# SERDES_16G0 register map
Vendor: Texas Instruments
Registers are 32-bit, read-write, reset 0x0 unless marked. A register's access mark holds for its fields unless they carry their own. Offsets are as the file gives them; [hi:lo] are bit positions; {n}, {i} and the like mark numbered series; 'fields as' and 'values as' point back to an identical list.

## SERDES_16G0 (part 4 of 5)
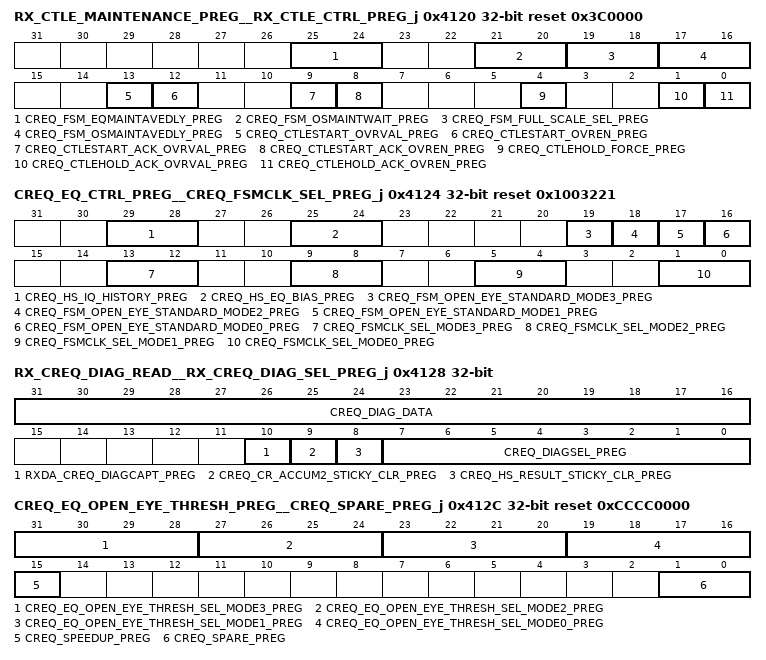
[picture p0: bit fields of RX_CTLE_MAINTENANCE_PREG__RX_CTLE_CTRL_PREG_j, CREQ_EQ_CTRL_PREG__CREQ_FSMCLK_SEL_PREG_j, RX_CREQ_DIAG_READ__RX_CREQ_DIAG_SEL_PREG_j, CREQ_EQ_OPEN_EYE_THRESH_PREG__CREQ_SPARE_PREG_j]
0x4120 RX_CTLE_MAINTENANCE_PREG__RX_CTLE_CTRL_PREG_j reset 0x3C0000 — Receive clock path CTLE Control register. Offset = 4120h + (j * 400h); where j = 0h to 1h
  [25:24] CREQ_FSM_EQMAINTAVEDLY_PREG — Receive clock path CTLE equalization maintenance averaging timer:
  [21:20] CREQ_FSM_OSMAINTWAIT_PREG — Receive clock path CTLE offset calibration maintenance hold off timer:
  [19:18] CREQ_FSM_FULL_SCALE_SEL_PREG — Offset maintenance filter threshold.
  [17:16] CREQ_FSM_OSMAINTAVEDLY_PREG — Receive clock path CTLE offset calibration maintenance =averaging timer:
  [13] CREQ_CTLESTART_OVRVAL_PREG — When creq_ctlestart_ovren_preg is asserted this value overrides the receive clock path CTLE FSM start signal from the clock path controller.
  [12] CREQ_CTLESTART_OVREN_PREG — Receive clock path CTLE start active high override enable.
  [9] CREQ_CTLESTART_ACK_OVRVAL_PREG — When creq_ctlestart_ack_ovren_preg is asserted this value overrides the receive clock path CTLE FSM start signal acknowledge to the clock path controller.
  [8] CREQ_CTLESTART_ACK_OVREN_PREG — Receive clock path CTLE start acknowledge active high override enable.
  [4] CREQ_CTLEHOLD_FORCE_PREG — Receive clock path CTLE FSM hold active high force:
  [1] CREQ_CTLEHOLD_ACK_OVRVAL_PREG — Receive clock path CTLE FSM hold acknowledge active high override value:
  [0] CREQ_CTLEHOLD_ACK_OVREN_PREG — Receive clock path CTLE FSM hold acknowledge active high override enable:
0x4124 CREQ_EQ_CTRL_PREG__CREQ_FSMCLK_SEL_PREG_j reset 0x1003221 — Receive clock recovery and equalization (CREQ) state machine clock division register. Offset = 4124h + (j * 400h); where j = 0h to 1h
  [29:28] CREQ_HS_IQ_HISTORY_PREG — Lookback history selection for Undereq/Overeq function.
  [25:24] CREQ_HS_EQ_BIAS_PREG — Programmable bias control where larger values provides more equalization.
  [19] CREQ_FSM_OPEN_EYE_STANDARD_MODE3_PREG — When asserted, clock path equalization will not be performed when xcvr_standard_mode_ln{15:0}[2:0] is 3'b011.
  [18] CREQ_FSM_OPEN_EYE_STANDARD_MODE2_PREG — When asserted, clock path equalization will not be performed when xcvr_standard_mode_ln{15:0}[2:0] is 3'b010.
  [17] CREQ_FSM_OPEN_EYE_STANDARD_MODE1_PREG — When asserted, clock path equalization will not be performed when xcvr_standard_mode_ln{15:0}[2:0] is 3'b001.
  [16] CREQ_FSM_OPEN_EYE_STANDARD_MODE0_PREG — When asserted, clock path equalization will not be performed when xcvr_standard_mode_ln{15:0}[2:0] is 3'b000.
  [13:12] CREQ_FSMCLK_SEL_MODE3_PREG — This value sets the Clock recovery and equalization (CREQ) state machine clock, fsmclk, division ratio from the Lane Standards Decoder when xcvr_standard_mode_ln{15:0} [2:0] is 3'b011.
  [9:8] CREQ_FSMCLK_SEL_MODE2_PREG — This value sets the Clock recovery and equalization (CREQ) state machine clock, fsmclk, division ratio from the Lane Standards Decoder when xcvr_standard_mode_ln{15:0} [2:0] is 3'b010.
  [5:4] CREQ_FSMCLK_SEL_MODE1_PREG — This value sets the Clock recovery and equalization (CREQ) state machine clock, fsmclk, division ratio from the Lane Standards Decoder when xcvr_standard_mode_ln{15:0} [2:0] is 3'b001.
  [1:0] CREQ_FSMCLK_SEL_MODE0_PREG — This value sets the Clock recovery and equalization (CREQ) state machine clock, fsmclk, division ratio from the Lane Standards Decoder when xcvr_standard_mode_ln{15:0} [2:0] is 3'b000.
0x4128 RX_CREQ_DIAG_READ__RX_CREQ_DIAG_SEL_PREG_j access per field — Receive clock recovery and equalization (CREQ) diagnostic bus control register. Offset = 4128h + (j * 400h); where j = 0h to 1h
  [31:16] CREQ_DIAG_DATA ro — Clock recovery and equalization (CREQ) diagnostic bus.
  [10] RXDA_CREQ_DIAGCAPT_PREG rw — Clock recovery and equalization (CREQ) diagnostic bus active high capture signal:
  [9] CREQ_CR_ACCUM2_STICKY_CLR_PREG rw — Clock recovery integral path accumulator sticky saturation clear:
  [8] CREQ_HS_RESULT_STICKY_CLR_PREG rw — Clock path equalization high-speed circuit result sticky saturation clear:
  [7:0] CREQ_DIAGSEL_PREG rw — Clock recovery and equalization (CREQ) diagnostic bus selection:
0x412C CREQ_EQ_OPEN_EYE_THRESH_PREG__CREQ_SPARE_PREG_j reset 0xCCCC0000 — CREQ spare and speedup register Offset = 412Ch + (j * 400h); where j = 0h to 1h
  [31:28] CREQ_EQ_OPEN_EYE_THRESH_SEL_MODE3_PREG — Selects number of ctle_open_eye (bad codes) to declare a CTLE LUT setting invalid when xcvr_standard_mode_ln_{15:0}[2:0] is 3'b011.
  [27:24] CREQ_EQ_OPEN_EYE_THRESH_SEL_MODE2_PREG — Selects number of ctle_open_eye (bad codes) to declare a CTLE LUT setting invalid when xcvr_standard_mode_ln_{15:0}[2:0] is 3'b010.
  [23:20] CREQ_EQ_OPEN_EYE_THRESH_SEL_MODE1_PREG — Selects number of ctle_open_eye (bad codes) to declare a CTLE LUT setting invalid when xcvr_standard_mode_ln_{15:0}[2:0] is 3'b001.
  [19:16] CREQ_EQ_OPEN_EYE_THRESH_SEL_MODE0_PREG — Selects number of ctle_open_eye (bad codes) to declare a CTLE LUT setting invalid when xcvr_standard_mode_ln_{15:0}[2:0] is 3'b000.
  [15] CREQ_SPEEDUP_PREG — CREQ active high simulation only speedup enable:
  [1:0] CREQ_SPARE_PREG — Spare register bits assigned to rxda_creq_spare[1:0].
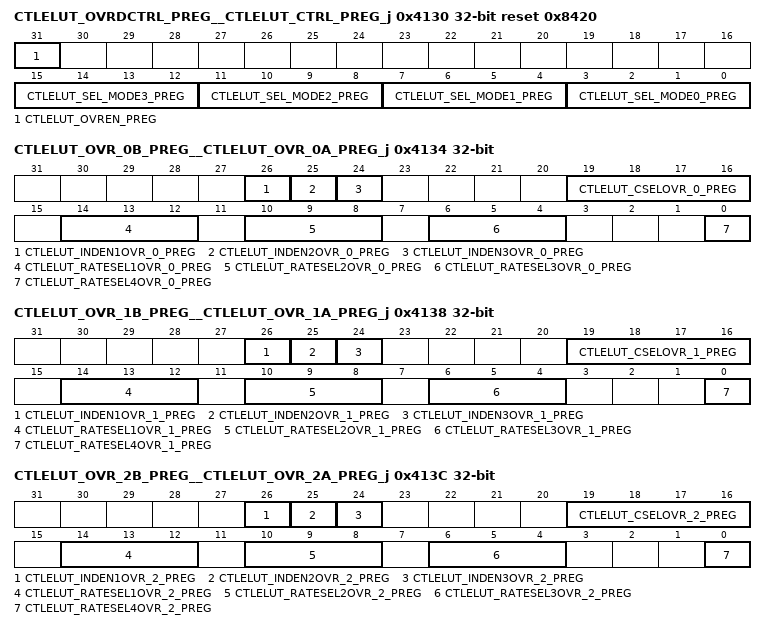
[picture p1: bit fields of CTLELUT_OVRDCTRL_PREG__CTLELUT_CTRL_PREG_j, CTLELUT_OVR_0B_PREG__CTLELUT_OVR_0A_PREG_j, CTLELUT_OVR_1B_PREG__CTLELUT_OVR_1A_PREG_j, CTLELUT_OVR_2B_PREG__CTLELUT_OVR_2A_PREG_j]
0x4130 CTLELUT_OVRDCTRL_PREG__CTLELUT_CTRL_PREG_j reset 0x8420 — Receive clock Path CTLE LUT control register. Offset = 4130h + (j * 400h); where j = 0h to 1h
  [31] CTLELUT_OVREN_PREG — Receive clock Path CTLE LUT active high override table enable:
  [15:12] CTLELUT_SEL_MODE3_PREG — Selects the CTLE LUT from the Lane Standards Decoder to use when xcvr_standard_mode_ln_{15:0}[2:0] is 3'b011.
  [11:8] CTLELUT_SEL_MODE2_PREG — Selects the CTLE LUT from the Lane Standards Decoder to use when xcvr_standard_mode_ln_{15:0}[2:0] is 3'b010.
  [7:4] CTLELUT_SEL_MODE1_PREG — Selects the CTLE LUT from the Lane Standards Decoder to use when xcvr_standard_mode_ln_{15:0}[2:0] is 3'b001.
  [3:0] CTLELUT_SEL_MODE0_PREG — Selects the CTLE LUT from the Lane Standards Decoder to use when xcvr_standard_mode_ln_{15:0}[2:0] is 3'b000.
0x4134 CTLELUT_OVR_0B_PREG__CTLELUT_OVR_0A_PREG_j — Receive clock path CTLE LUT ratesel override, entry 0 register. Offset = 4134h + (j * 400h); where j = 0h to 1h
  [26] CTLELUT_INDEN1OVR_0_PREG — Clock Path CTLE LUT stage 1 active high inductor enable override, Entry 0
  [25] CTLELUT_INDEN2OVR_0_PREG — Clock Path CTLE LUT stage 2 active high inductor enable override, Entry 0
  [24] CTLELUT_INDEN3OVR_0_PREG — Clock Path CTLE LUT stage 3 active high inductor enable override, Entry 0
  [19:16] CTLELUT_CSELOVR_0_PREG — Clock Path CTLE LUT binary encoded boost / peaking control override, Entry 0
  [14:12] CTLELUT_RATESEL1OVR_0_PREG — Clock Path CTLE LUT ratesel1 Override Value, Entry 0
  [10:8] CTLELUT_RATESEL2OVR_0_PREG — Clock Path CTLE LUT stage 2 thermometer encoded data rate per bandwidth selection override, Entry 0
  [6:4] CTLELUT_RATESEL3OVR_0_PREG — Clock Path CTLE LUT stage 3 thermometer encoded data rate per bandwidth selection override, Entry 0
  [0] CTLELUT_RATESEL4OVR_0_PREG — Clock Path CTLE LUT stage 4 data rate per bandwidth selection override, Entry 0
0x4138 CTLELUT_OVR_1B_PREG__CTLELUT_OVR_1A_PREG_j — Receive clock path CTLE LUT ratesel override, entry 1 register. Offset = 4138h + (j * 400h); where j = 0h to 1h
  [26] CTLELUT_INDEN1OVR_1_PREG — Clock Path CTLE LUT stage 1 active high inductor enable override, Entry 1
  [25] CTLELUT_INDEN2OVR_1_PREG — Clock Path CTLE LUT stage 2 active high inductor enable override, Entry 1
  [24] CTLELUT_INDEN3OVR_1_PREG — Clock Path CTLE LUT stage 3 active high inductor enable override, Entry 1
  [19:16] CTLELUT_CSELOVR_1_PREG — Clock Path CTLE LUT binary encoded boost / peaking control override, Entry 1
  [14:12] CTLELUT_RATESEL1OVR_1_PREG — Clock Path CTLE LUT stage 1 thermometer encoded data rate per bandwidth selection override, Entry 1
  [10:8] CTLELUT_RATESEL2OVR_1_PREG — Clock Path CTLE LUT stage 2 thermometer encoded data rate per bandwidth selection override, Entry 1
  [6:4] CTLELUT_RATESEL3OVR_1_PREG — Clock Path CTLE LUT stage 3 thermometer encoded data rate per bandwidth selection override, Entry 1
  [0] CTLELUT_RATESEL4OVR_1_PREG — Clock Path CTLE LUT stage 4 data rate per bandwidth selection override, Entry 1
0x413C CTLELUT_OVR_2B_PREG__CTLELUT_OVR_2A_PREG_j — Receive clock path CTLE LUT ratesel override, entry 2 register. Offset = 413Ch + (j * 400h); where j = 0h to 1h
  [26] CTLELUT_INDEN1OVR_2_PREG — Clock Path CTLE LUT stage 1 active high inductor enable override, Entry 2
  [25] CTLELUT_INDEN2OVR_2_PREG — Clock Path CTLE LUT stage 2 active high inductor enable override, Entry 2
  [24] CTLELUT_INDEN3OVR_2_PREG — Clock Path CTLE LUT stage 3 active high inductor enable override, Entry 2
  [19:16] CTLELUT_CSELOVR_2_PREG — Clock Path CTLE LUT binary encoded boost / peaking control override, Entry 2
  [14:12] CTLELUT_RATESEL1OVR_2_PREG — Clock Path CTLE LUT stage 1 thermometer encoded data rate per bandwidth selection override, Entry 2
  [10:8] CTLELUT_RATESEL2OVR_2_PREG — Clock Path CTLE LUT stage 2 thermometer encoded data rate per bandwidth selection override, Entry 2
  [6:4] CTLELUT_RATESEL3OVR_2_PREG — Clock Path CTLE LUT stage 3 thermometer encoded data rate per bandwidth selection override, Entry 2
  [0] CTLELUT_RATESEL4OVR_2_PREG — Clock Path CTLE LUT stage 4 data rate per bandwidth selection override, Entry 2
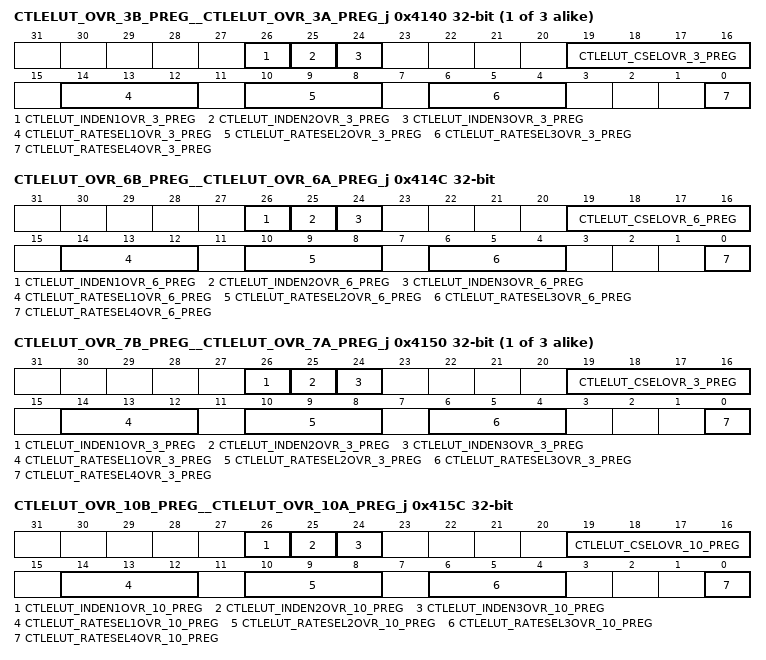
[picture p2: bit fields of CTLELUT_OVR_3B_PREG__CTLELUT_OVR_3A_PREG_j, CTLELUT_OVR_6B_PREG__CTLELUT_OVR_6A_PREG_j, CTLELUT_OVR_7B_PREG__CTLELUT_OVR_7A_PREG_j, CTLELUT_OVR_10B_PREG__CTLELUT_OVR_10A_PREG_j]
{0x4134+4i} CTLELUT_OVR_{i}B_PREG__CTLELUT_OVR_{i}A_PREG_j (i=3..5) — Receive clock path CTLE LUT ratesel override, entry {i} register. Offset = {4i+4128}h + (j * 400h); where j = 0h to 1h
  [26] CTLELUT_INDEN1OVR_{i}_PREG — Clock Path CTLE LUT stage 1 active high inductor enable override, Entry {i}
  [25] CTLELUT_INDEN2OVR_{i}_PREG — Clock Path CTLE LUT stage 2 active high inductor enable override, Entry {i}
  [24] CTLELUT_INDEN3OVR_{i}_PREG — Clock Path CTLE LUT stage 3 active high inductor enable override, Entry {i}
  [19:16] CTLELUT_CSELOVR_{i}_PREG — Clock Path CTLE LUT binary encoded boost / peaking control override, Entry {i}
  [14:12] CTLELUT_RATESEL1OVR_{i}_PREG — Clock Path CTLE LUT stage 1 thermometer encoded data rate per bandwidth selection override, Entry {i}
  [10:8] CTLELUT_RATESEL2OVR_{i}_PREG — Clock Path CTLE LUT stage 2 thermometer encoded data rate per bandwidth selection override, Entry {i}
  [6:4] CTLELUT_RATESEL3OVR_{i}_PREG — Clock Path CTLE LUT stage 3 thermometer encoded data rate per bandwidth selection override, Entry {i}
  [0] CTLELUT_RATESEL4OVR_{i}_PREG — Clock Path CTLE LUT stage 4 data rate per bandwidth selection override, Entry {i}
0x414C CTLELUT_OVR_6B_PREG__CTLELUT_OVR_6A_PREG_j — Receive clock path CTLE LUT ratesel override, entry 6 register. Offset = 414Ch + (j * 400h); where j = 0h to 1h
  [26] CTLELUT_INDEN1OVR_6_PREG — Clock Path CTLE LUT stage 1 active high inductor enable override, Entry 6
  [25] CTLELUT_INDEN2OVR_6_PREG — Clock Path CTLE LUT stage 2 active high inductor enable override, Entry 6
  [24] CTLELUT_INDEN3OVR_6_PREG — Clock Path CTLE LUT stage 3 active high inductor enable override, Entry 6
  [19:16] CTLELUT_CSELOVR_6_PREG — Clock Path CTLE LUT binary encoded boost / peaking control override, Entry 6
  [14:12] CTLELUT_RATESEL1OVR_6_PREG — Clock Path CTLE LUT stage 1 thermometer encoded data rate per bandwidth selection override, Entry 6
  [10:8] CTLELUT_RATESEL2OVR_6_PREG — Clock Path CTLE LUT stage 2 thermometer encoded data rate per bandwidth selection override, Entry 6
  [6:4] CTLELUT_RATESEL3OVR_6_PREG — Clock Path CTLE LUT stage 3 thermometer encoded data rate per bandwidth selection override, Entry 6
  [0] CTLELUT_RATESEL4OVR_6_PREG — Clock Path CTLE LUT stage 4 data rate per bandwidth selection override, Entry 6
{0x4134+4i} CTLELUT_OVR_{i}B_PREG__CTLELUT_OVR_{i}A_PREG_j (i=7..9) — Receive clock path CTLE LUT ratesel override, entry {i} register. Offset = {4i+4122}h + (j * 400h); where j = 0h to 1h
  fields as CTLELUT_OVR_3B_PREG__CTLELUT_OVR_3A_PREG_j
0x415C CTLELUT_OVR_10B_PREG__CTLELUT_OVR_10A_PREG_j — Receive clock path CTLE LUT ratesel override, entry 10 register. Offset = 415Ch + (j * 400h); where j = 0h to 1h
  [26] CTLELUT_INDEN1OVR_10_PREG — Clock Path CTLE LUT stage 1 active high inductor enable override, Entry 10
  [25] CTLELUT_INDEN2OVR_10_PREG — Clock Path CTLE LUT stage 2 active high inductor enable override, Entry 10
  [24] CTLELUT_INDEN3OVR_10_PREG — Clock Path CTLE LUT stage 3 active high inductor enable override, Entry 10
  [19:16] CTLELUT_CSELOVR_10_PREG — Clock Path CTLE LUT binary encoded boost / peaking control override, Entry 10
  [14:12] CTLELUT_RATESEL1OVR_10_PREG — Clock Path CTLE LUT stage 1 thermometer encoded data rate per bandwidth selection override, Entry 10
  [10:8] CTLELUT_RATESEL2OVR_10_PREG — Clock Path CTLE LUT stage 2 thermometer encoded data rate per bandwidth selection override, Entry 10
  [6:4] CTLELUT_RATESEL3OVR_10_PREG — Clock Path CTLE LUT stage 3 thermometer encoded data rate per bandwidth selection override, Entry 10
  [0] CTLELUT_RATESEL4OVR_10_PREG — Clock Path CTLE LUT stage 4 data rate per bandwidth selection override, Entry 10
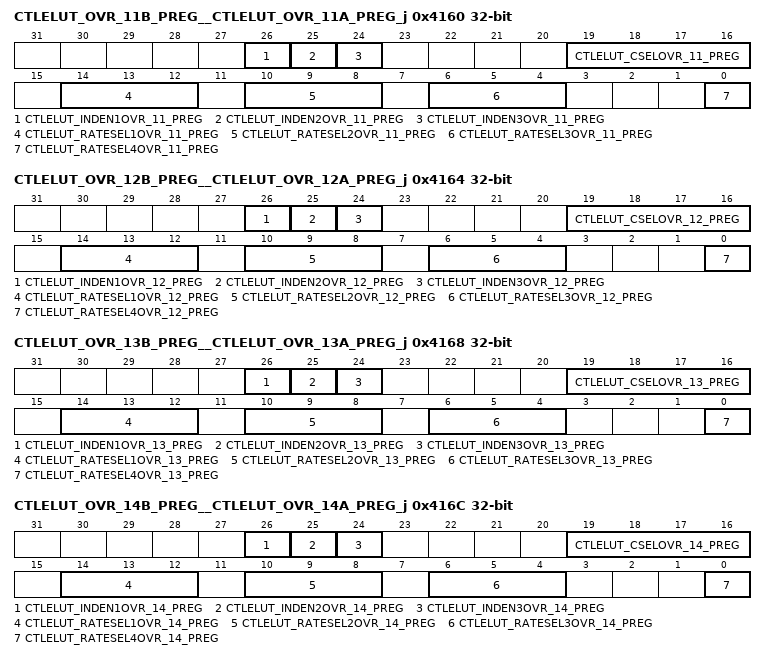
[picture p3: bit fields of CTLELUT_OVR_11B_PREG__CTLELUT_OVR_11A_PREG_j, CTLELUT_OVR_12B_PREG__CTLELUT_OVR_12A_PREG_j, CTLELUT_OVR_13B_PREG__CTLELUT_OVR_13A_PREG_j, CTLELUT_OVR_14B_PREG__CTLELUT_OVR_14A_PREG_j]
0x4160 CTLELUT_OVR_11B_PREG__CTLELUT_OVR_11A_PREG_j — Receive clock path CTLE LUT ratesel override, entry 11 register. Offset = 4160h + (j * 400h); where j = 0h to 1h
  [26] CTLELUT_INDEN1OVR_11_PREG — Clock Path CTLE LUT stage 1 active high inductor enable override, Entry 11
  [25] CTLELUT_INDEN2OVR_11_PREG — Clock Path CTLE LUT stage 2 active high inductor enable override, Entry 11
  [24] CTLELUT_INDEN3OVR_11_PREG — Clock Path CTLE LUT stage 3 active high inductor enable override, Entry 11
  [19:16] CTLELUT_CSELOVR_11_PREG — Clock Path CTLE LUT binary encoded boost / peaking control override, Entry 11
  [14:12] CTLELUT_RATESEL1OVR_11_PREG — Clock Path CTLE LUT stage 1 thermometer encoded data rate per bandwidth selection override, Entry 11
  [10:8] CTLELUT_RATESEL2OVR_11_PREG — Clock Path CTLE LUT stage 2 thermometer encoded data rate per bandwidth selection override, Entry 11
  [6:4] CTLELUT_RATESEL3OVR_11_PREG — Clock Path CTLE LUT stage 3 thermometer encoded data rate per bandwidth selection override, Entry 11
  [0] CTLELUT_RATESEL4OVR_11_PREG — Clock Path CTLE LUT stage 4 data rate per bandwidth selection override, Entry 11
0x4164 CTLELUT_OVR_12B_PREG__CTLELUT_OVR_12A_PREG_j — Receive clock path CTLE LUT ratesel override, entry 12 register. Offset = 4164h + (j * 400h); where j = 0h to 1h
  [26] CTLELUT_INDEN1OVR_12_PREG — Clock Path CTLE LUT stage 1 active high inductor enable override, Entry 12
  [25] CTLELUT_INDEN2OVR_12_PREG — Clock Path CTLE LUT stage 2 active high inductor enable override, Entry 12
  [24] CTLELUT_INDEN3OVR_12_PREG — Clock Path CTLE LUT stage 3 active high inductor enable override, Entry 12
  [19:16] CTLELUT_CSELOVR_12_PREG — Clock Path CTLE LUT binary encoded boost / peaking control override, Entry 12
  [14:12] CTLELUT_RATESEL1OVR_12_PREG — Clock Path CTLE LUT stage 1 thermometer encoded data rate per bandwidth selection override, Entry 12
  [10:8] CTLELUT_RATESEL2OVR_12_PREG — Clock Path CTLE LUT stage 2 thermometer encoded data rate per bandwidth selection override, Entry 12
  [6:4] CTLELUT_RATESEL3OVR_12_PREG — Clock Path CTLE LUT stage 3 thermometer encoded data rate per bandwidth selection override, Entry 12
  [0] CTLELUT_RATESEL4OVR_12_PREG — Clock Path CTLE LUT stage 4 tdata rate per bandwidth selection override, Entry 12
0x4168 CTLELUT_OVR_13B_PREG__CTLELUT_OVR_13A_PREG_j — Receive clock path CTLE LUT ratesel override, entry 13 register. Offset = 4168h + (j * 400h); where j = 0h to 1h
  [26] CTLELUT_INDEN1OVR_13_PREG — Clock Path CTLE LUT stage 1 active high inductor enable override, Entry 13
  [25] CTLELUT_INDEN2OVR_13_PREG — Clock Path CTLE LUT stage 2 active high inductor enable override, Entry 13
  [24] CTLELUT_INDEN3OVR_13_PREG — Clock Path CTLE LUT stage 3 active high inductor enable override, Entry 13
  [19:16] CTLELUT_CSELOVR_13_PREG — Clock Path CTLE LUT binary encoded boost / peaking control override, Entry 13
  [14:12] CTLELUT_RATESEL1OVR_13_PREG — Clock Path CTLE LUT stage 1 thermometer encoded data rate per bandwidth selection override, Entry 13
  [10:8] CTLELUT_RATESEL2OVR_13_PREG — Clock Path CTLE LUT stage 2 thermometer encoded data rate per bandwidth selection override, Entry 13
  [6:4] CTLELUT_RATESEL3OVR_13_PREG — Clock Path CTLE LUT stage 3 thermometer encoded data rate per bandwidth selection override, Entry 13
  [0] CTLELUT_RATESEL4OVR_13_PREG — Clock Path CTLE LUT stage 4 data rate per bandwidth selection override, Entry 13
0x416C CTLELUT_OVR_14B_PREG__CTLELUT_OVR_14A_PREG_j — Receive clock path CTLE LUT ratesel override, entry 14 register. Offset = 416Ch + (j * 400h); where j = 0h to 1h
  [26] CTLELUT_INDEN1OVR_14_PREG — Clock Path CTLE LUT stage 1 active high inductor enable override, Entry 14
  [25] CTLELUT_INDEN2OVR_14_PREG — Clock Path CTLE LUT stage 2 active high inductor enable override, Entry 14
  [24] CTLELUT_INDEN3OVR_14_PREG — Clock Path CTLE LUT stage 3 active high inductor enable override, Entry 14
  [19:16] CTLELUT_CSELOVR_14_PREG — Clock Path CTLE LUT binary encoded boost / peaking control override, Entry 14
  [14:12] CTLELUT_RATESEL1OVR_14_PREG — Clock Path CTLE LUT stage 1 thermometer encoded data rate per bandwidth selection override, Entry 14
  [10:8] CTLELUT_RATESEL2OVR_14_PREG — Clock Path CTLE LUT stage 2 thermometer encoded data rate per bandwidth selection override, Entry 14
  [6:4] CTLELUT_RATESEL3OVR_14_PREG — Clock Path CTLE LUT stage 3 thermometer encoded data rate per bandwidth selection override, Entry 14
  [0] CTLELUT_RATESEL4OVR_14_PREG — Clock Path CTLE LUT stage 4 data rate per bandwidth selection override, Entry 14
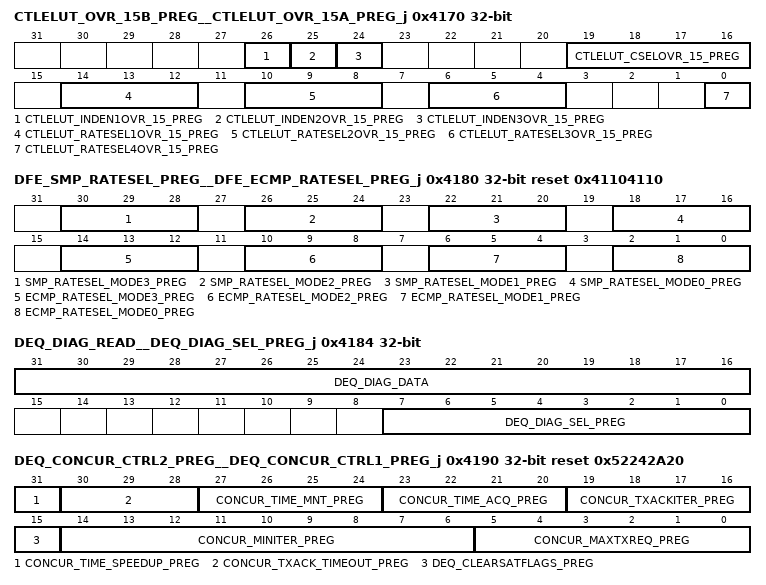
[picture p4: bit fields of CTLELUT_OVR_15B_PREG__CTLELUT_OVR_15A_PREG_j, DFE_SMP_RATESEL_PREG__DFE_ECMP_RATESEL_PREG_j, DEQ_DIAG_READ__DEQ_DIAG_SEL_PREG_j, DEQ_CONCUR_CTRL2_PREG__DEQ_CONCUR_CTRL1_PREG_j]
0x4170 CTLELUT_OVR_15B_PREG__CTLELUT_OVR_15A_PREG_j — Receive clock path CTLE LUT ratesel override, entry 15 register. Offset = 4170h + (j * 400h); where j = 0h to 1h
  [26] CTLELUT_INDEN1OVR_15_PREG — Clock Path CTLE LUT stage 1 active high inductor enable override, Entry 15
  [25] CTLELUT_INDEN2OVR_15_PREG — Clock Path CTLE LUT stage 2 active high inductor enable override, Entry 15
  [24] CTLELUT_INDEN3OVR_15_PREG — Clock Path CTLE LUT stage 3 active high inductor enable override, Entry 15
  [19:16] CTLELUT_CSELOVR_15_PREG — Clock Path CTLE LUT binary encoded boost / peaking control override, Entry 15
  [14:12] CTLELUT_RATESEL1OVR_15_PREG — Clock Path CTLE LUT stage 1 thermometer encoded data rate per bandwidth selection override, Entry 15
  [10:8] CTLELUT_RATESEL2OVR_15_PREG — Clock Path CTLE LUT stage 2 thermometer encoded data rate per bandwidth selection override, Entry 15
  [6:4] CTLELUT_RATESEL3OVR_15_PREG — Clock Path CTLE LUT stage 3 thermometer encoded data rate per bandwidth selection override, Entry 15
  [0] CTLELUT_RATESEL4OVR_15_PREG — Clock Path CTLE LUT stage 4 data rate per bandwidth selection override, Entry 15
0x4180 DFE_SMP_RATESEL_PREG__DFE_ECMP_RATESEL_PREG_j reset 0x41104110 — Receive data path DFE error comparator rate selection register. Offset = 4180h + (j * 400h); where j = 0h to 1h
  [30:28] SMP_RATESEL_MODE3_PREG — This value sets the receive data path DFE sampler rate selection when xcvr_standard_mode_ln_{15:0}[2:0] is 3'b011.
  [26:24] SMP_RATESEL_MODE2_PREG — This value sets the receive data path DFE sampler rate selection when xcvr_standard_mode_ln_{15:0}[2:0] is 3'b010.
  [22:20] SMP_RATESEL_MODE1_PREG — This value sets the receive data path DFE sampler rate selection when xcvr_standard_mode_ln_{15:0}[2:0] is 3'b001.
  [18:16] SMP_RATESEL_MODE0_PREG — This value sets the receive data path DFE sampler rate selection when xcvr_standard_mode_ln_{15:0}[2:0] is 3'b000.
  [14:12] ECMP_RATESEL_MODE3_PREG — This value sets the Lane Standards Decoder driven value for receive data path DFE error comparator rate selection when xcvr_standard_mode_ln_{15:0}[2:0] is 3'b011.
  [10:8] ECMP_RATESEL_MODE2_PREG — This value sets the Lane Standards Decoder driven value for receive data path DFE error comparator rate selection when xcvr_standard_mode_ln_{15:0}[2:0] is 3'b010.
  [6:4] ECMP_RATESEL_MODE1_PREG — This value sets the Lane Standards Decoder driven value for receive data path DFE error comparator rate selection when xcvr_standard_mode_ln_{15:0}[2:0] is 3'b001.
  [2:0] ECMP_RATESEL_MODE0_PREG — This value sets the Lane Standards Decoder driven value for receive data path DFE error comparator rate selection when xcvr_standard_mode_ln_{15:0}[2:0] is 3'b000.
0x4184 DEQ_DIAG_READ__DEQ_DIAG_SEL_PREG_j access per field — Receive data path equalization (DEQ) diagnostic bus control register. Offset = 4184h + (j * 400h); where j = 0h to 1h
  [31:16] DEQ_DIAG_DATA ro — Receive data path equalization (DEQ) diagnostic bus.
  [7:0] DEQ_DIAG_SEL_PREG rw — Receive data path equalization (DEQ) diagnostic bus selection:
0x4188 DEQ_PHALIGN_CTRL_j reset 0x3 — Receive data path phase alignment control register Offset = 4188h + (j * 400h); where j = 0h to 1h
  [1:0] DEQ_PHALIGN_SAMPSIZE_PREG — Selection of sample size used to determine the position o f the ecmp_clk_n rising edge in the ST_B1_EVAL state of the rxana_deq_phalign FSM:
0x4190 DEQ_CONCUR_CTRL2_PREG__DEQ_CONCUR_CTRL1_PREG_j access per field reset 0x52242A20 — Receive data path concurrent equalization control register 1. Offset = 4190h + (j * 400h); where j = 0h to 1h
  [31] CONCUR_TIME_SPEEDUP_PREG rw — Concurrent equalization active high simulation speedup enable:
  [30:28] CONCUR_TXACK_TIMEOUT_PREG rw — Receive closed-eye data path equalization timeout waiting for next rx_eq_eval assertion.
  [27:24] CONCUR_TIME_MNT_PREG rw — Receive closed-eye data path equalization concurrent process time during maintenance.
  [23:20] CONCUR_TIME_ACQ_PREG rw — Receive closed-eye data path equalization concurrent process time during acquisition.
  [19:16] CONCUR_TXACKITER_PREG rw — Receive closed-eye data path equalization minimum iterations of concur and tau processes after a far-end transmit equalization acknowledgement before a new far-end transmit request can be made.
  [15] DEQ_CLEARSATFLAGS_PREG wo — Toggle style bit which when written high clears the equalization saturation flags of all concurrent algorithms.
  [14:6] CONCUR_MINITER_PREG rw — Receive closed-eye data path equalization minimum iterations of concur and tau processes during acquisition.
  [5:0] CONCUR_MAXTXREQ_PREG rw — Receive closed-eye data path equalization maximum far-end transmit equalization requests.
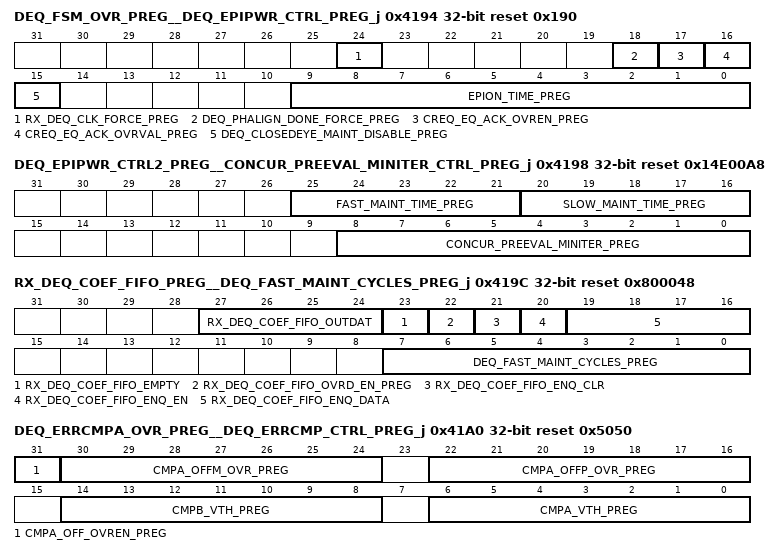
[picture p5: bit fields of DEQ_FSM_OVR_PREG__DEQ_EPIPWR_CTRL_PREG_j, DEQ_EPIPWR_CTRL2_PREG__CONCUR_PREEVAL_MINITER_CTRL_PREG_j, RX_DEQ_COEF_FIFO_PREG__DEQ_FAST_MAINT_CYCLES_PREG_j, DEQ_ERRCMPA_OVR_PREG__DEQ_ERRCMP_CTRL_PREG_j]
0x4194 DEQ_FSM_OVR_PREG__DEQ_EPIPWR_CTRL_PREG_j reset 0x190 — Receive data path equalization (DEQ) and EPI control register. Offset = 4194h + (j * 400h); where j = 0h to 1h
  [24] RX_DEQ_CLK_FORCE_PREG — When asserted, rx_deq_clk remains on when ln_rxctrl_deq_fsm whenever rxdatclk is on.
  [18] DEQ_PHALIGN_DONE_FORCE_PREG — rxda_deq_phalign_done force.
  [17] CREQ_EQ_ACK_OVREN_PREG — rxda_creq_eq_req acknowledgement override enable.
  [16] CREQ_EQ_ACK_OVRVAL_PREG — rxda_creq_eq_req acknowledgement override value.
  [15] DEQ_CLOSEDEYE_MAINT_DISABLE_PREG — Receive data path closed-eye equalization active high disable.
  [9:0] EPION_TIME_PREG — Receive data path equalization EPI power on settling time.
0x4198 DEQ_EPIPWR_CTRL2_PREG__CONCUR_PREEVAL_MINITER_CTRL_PREG_j reset 0x14E00A8 — DEQ_EPIPWR_CTRL2_PREG__CONCUR_PREEVAL_MINITER_CTRL_PREG Offset = 4198h + (j * 400h); where j = 0h to 1h
  [25:21] FAST_MAINT_TIME_PREG — Receive data path closed-eye equalization fast maintenance cycle hold off time.
  [20:16] SLOW_MAINT_TIME_PREG — Receive data path closed-eye equalization slow maintenance cycle hold off time.
  [8:0] CONCUR_PREEVAL_MINITER_PREG — Receive closed-eye data path equalization minimum iterations of concur and tau processes during the acquisition phase prior to the initial rx_eq_eval assertion when deq_closedeye_mode = 2'b10.
0x419C RX_DEQ_COEF_FIFO_PREG__DEQ_FAST_MAINT_CYCLES_PREG_j access per field reset 0x800048 — Receive data path equalization (DEQ) fast maintainance cycles register Offset = 419Ch + (j * 400h); where j = 0h to 1h
  [27:24] RX_DEQ_COEF_FIFO_OUTDAT ro — Receive data path equalization emulation mode FIFO output data:
  [23] RX_DEQ_COEF_FIFO_EMPTY ro — Receive data path equalization emulation mode FIFO empty :
  [22] RX_DEQ_COEF_FIFO_OVRD_EN_PREG rw — Receive data path equalization emulation mode FIFO output active high enable:
  [21] RX_DEQ_COEF_FIFO_ENQ_CLR wo — Receive data path equalization emulation mode FIFO enqueue pointer clear:
  [20] RX_DEQ_COEF_FIFO_ENQ_EN wo — Receive data path equalization emulation mode FIFO enqueue enable :
  [19:16] RX_DEQ_COEF_FIFO_ENQ_DATA wo — Receive data path equalization emulation mode FIFO write data :
  [7:0] DEQ_FAST_MAINT_CYCLES_PREG rw — Receive data path equalization (deq) fast maintenance cycle count:
0x41A0 DEQ_ERRCMPA_OVR_PREG__DEQ_ERRCMP_CTRL_PREG_j reset 0x5050 — Receive data path error comparator control register. Offset = 41A0h + (j * 400h); where j = 0h to 1h
  [31] CMPA_OFF_OVREN_PREG — Receive data path error comparator error comparator A offset override active high enable.
  [30:24] CMPA_OFFM_OVR_PREG — When cmpa_off_ovren_preg is asserted high, this active high binary encoded value will override the A comparator negative polarity DAC input which introduces a negative offset.
  [22:16] CMPA_OFFP_OVR_PREG — When cmpa_off_ovren_preg is asserted high, this active high binary encoded value will override the A comparator positive polarity DAC input which introduces a positive offset.
  [14:8] CMPB_VTH_PREG — Receive data path error comparator error comparator B target level, binary encoded.
  [6:0] CMPA_VTH_PREG — Receive data path error comparator error comparator A target level, binary encoded.
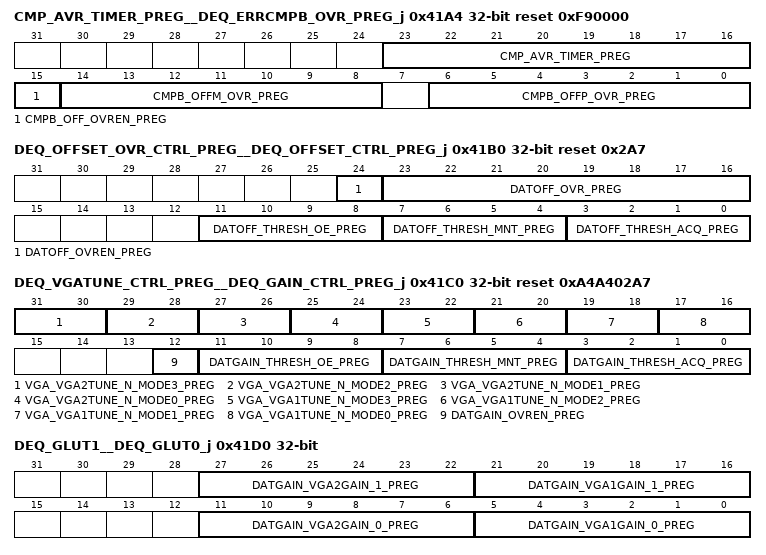
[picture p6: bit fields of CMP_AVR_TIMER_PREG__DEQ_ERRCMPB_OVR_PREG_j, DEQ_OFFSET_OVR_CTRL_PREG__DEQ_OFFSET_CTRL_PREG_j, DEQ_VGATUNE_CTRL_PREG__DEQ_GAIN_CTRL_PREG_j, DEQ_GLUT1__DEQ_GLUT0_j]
0x41A4 CMP_AVR_TIMER_PREG__DEQ_ERRCMPB_OVR_PREG_j reset 0xF90000 — Receive data path error comparator B override register. Offset = 41A4h + (j * 400h); where j = 0h to 1h
  [23:16] CMP_AVR_TIMER_PREG — Receive data path error comparators A and B average timer value.
  [15] CMPB_OFF_OVREN_PREG — Receive data path error comparator error comparator B offset override active high enable.
  [14:8] CMPB_OFFM_OVR_PREG — When cmpa_off_ovren_preg is asserted high, this active high binary encoded value will override the B comparator negative polarity DAC input which introduces a negative offset.
  [6:0] CMPB_OFFP_OVR_PREG — When cmpa_off_ovren_preg is asserted high, this active high binary encoded value will override the B comparator positive polarity DAC input which introduces a positive offset.
0x41B0 DEQ_OFFSET_OVR_CTRL_PREG__DEQ_OFFSET_CTRL_PREG_j reset 0x2A7 — Receive data path offset control register. Offset = 41B0h + (j * 400h); where j = 0h to 1h
  [24] DATOFF_OVREN_PREG — Receive data path offset active high override enable.
  [23:16] DATOFF_OVR_PREG — When datoff_ovren_preg is asserted high, this value overrides the data offset.
  [11:8] DATOFF_THRESH_OE_PREG — Receive data path offset accumulator threshold for open-eye standards.
  [7:4] DATOFF_THRESH_MNT_PREG — Receive data path offset accumulator threshold for maintenance.
  [3:0] DATOFF_THRESH_ACQ_PREG — Receive data path offset accumulator threshold for acquisition.
0x41C0 DEQ_VGATUNE_CTRL_PREG__DEQ_GAIN_CTRL_PREG_j reset 0xA4A402A7 — Receive data path gain and attenuation control register. Offset = 41C0h + (j * 400h); where j = 0h to 1h
  [31:30] VGA_VGA2TUNE_N_MODE3_PREG — This value sets the Lane Standards Decoder value when xcvr_standard_mode_ln_{15:0}[2:0] is 3'b011.
  [29:28] VGA_VGA2TUNE_N_MODE2_PREG — This value sets the Lane Standards Decoder value when xcvr_standard_mode_ln_{15:0}[2:0] is 3'b010.
  [27:26] VGA_VGA2TUNE_N_MODE1_PREG — This value sets the Lane Standards Decoder value when xcvr_standard_mode_ln_{15:0}[2:0] is 3'b001.
  [25:24] VGA_VGA2TUNE_N_MODE0_PREG — This value sets the Lane Standards Decoder value when xcvr_standard_mode_ln_{15:0}[2:0] is 3'b000.
  [23:22] VGA_VGA1TUNE_N_MODE3_PREG — This value sets the Lane Standards Decoder value when xcvr_standard_mode_ln_{15:0}[2:0] is 3'b011.
  [21:20] VGA_VGA1TUNE_N_MODE2_PREG — This value sets the Lane Standards Decoder value when xcvr_standard_mode_ln_{15:0}[2:0] is 3'b010.
  [19:18] VGA_VGA1TUNE_N_MODE1_PREG — This value sets the Lane Standards Decoder value when xcvr_standard_mode_ln_{15:0}[2:0] is 3'b001.
  [17:16] VGA_VGA1TUNE_N_MODE0_PREG — This value sets the Lane Standards Decoder value when xcvr_standard_mode_ln_{15:0}[2:0] is 3'b000.
  [12] DATGAIN_OVREN_PREG — Receive data path gain and attenuation look-up table pointer active high override enable.
  [11:8] DATGAIN_THRESH_OE_PREG — Receive data path gain accumulator threshold for open-eye standards.
  [7:4] DATGAIN_THRESH_MNT_PREG — Receive data path gain accumulator threshold for maintenance.
  [3:0] DATGAIN_THRESH_ACQ_PREG — Receive data path gain accumulator threshold for acquisition.
0x41D0 DEQ_GLUT1__DEQ_GLUT0_j — Receive data path equalization LUT gain, entry 0 register. Offset = 41D0h + (j * 400h); where j = 0h to 1h
  [27:22] DATGAIN_VGA2GAIN_1_PREG — Receive data path equalization LUT VGA2 peaking control, entry 1
  [21:16] DATGAIN_VGA1GAIN_1_PREG — Receive data path equalization LUT VGA1 peaking control, entry 1
  [11:6] DATGAIN_VGA2GAIN_0_PREG — Receive data path equalization LUT VGA2 peaking control, entry 0
  [5:0] DATGAIN_VGA1GAIN_0_PREG — Receive data path equalization LUT VGA1 peaking control, entry 0
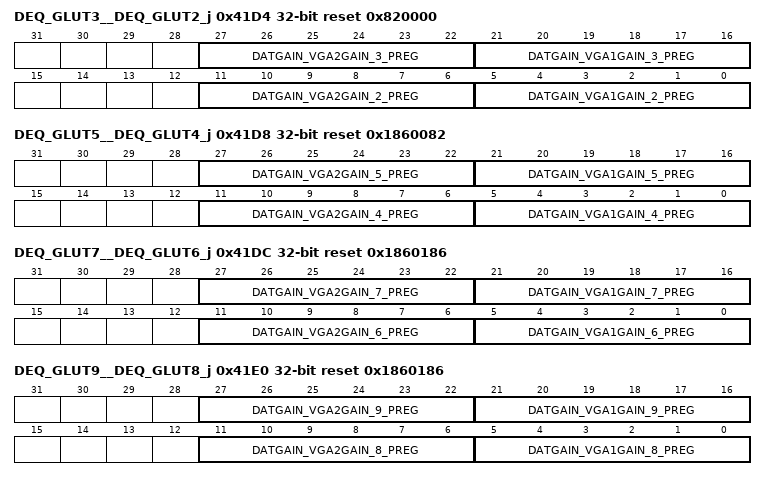
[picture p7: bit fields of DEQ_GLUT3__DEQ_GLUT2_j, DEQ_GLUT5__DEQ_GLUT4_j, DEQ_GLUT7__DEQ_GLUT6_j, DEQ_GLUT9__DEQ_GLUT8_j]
0x41D4 DEQ_GLUT3__DEQ_GLUT2_j reset 0x820000 — Receive data path equalization LUT gain, entry 2 register. Offset = 41D4h + (j * 400h); where j = 0h to 1h
  [27:22] DATGAIN_VGA2GAIN_3_PREG — Receive data path equalization LUT VGA2 peaking control, entry 3
  [21:16] DATGAIN_VGA1GAIN_3_PREG — Receive data path equalization LUT VGA1 peaking control, entry 3
  [11:6] DATGAIN_VGA2GAIN_2_PREG — Receive data path equalization LUT VGA2 peaking control, entry 2
  [5:0] DATGAIN_VGA1GAIN_2_PREG — Receive data path equalization LUT VGA1 peaking control, entry 2
0x41D8 DEQ_GLUT5__DEQ_GLUT4_j reset 0x1860082 — Receive data path equalization LUT gain, entry 4 register. Offset = 41D8h + (j * 400h); where j = 0h to 1h
  [27:22] DATGAIN_VGA2GAIN_5_PREG — Receive data path equalization LUT VGA2 peaking control, entry 5
  [21:16] DATGAIN_VGA1GAIN_5_PREG — Receive data path equalization LUT VGA1 peaking control, entry 5
  [11:6] DATGAIN_VGA2GAIN_4_PREG — Receive data path equalization LUT VGA2 peaking control, entry 4
  [5:0] DATGAIN_VGA1GAIN_4_PREG — Receive data path equalization LUT VGA1 peaking control, entry 4
0x41DC DEQ_GLUT7__DEQ_GLUT6_j reset 0x1860186 — Receive data path equalization LUT gain, entry 6 register. Offset = 41DCh + (j * 400h); where j = 0h to 1h
  [27:22] DATGAIN_VGA2GAIN_7_PREG — Receive data path equalization LUT VGA2 peaking control, entry 7
  [21:16] DATGAIN_VGA1GAIN_7_PREG — Receive data path equalization LUT VGA1 peaking control, entry 7
  [11:6] DATGAIN_VGA2GAIN_6_PREG — Receive data path equalization LUT VGA2 peaking control, entry 6
  [5:0] DATGAIN_VGA1GAIN_6_PREG — Receive data path equalization LUT VGA1 peaking control, entry 6
0x41E0 DEQ_GLUT9__DEQ_GLUT8_j reset 0x1860186 — Receive data path equalization LUT gain, entry 8 register. Offset = 41E0h + (j * 400h); where j = 0h to 1h
  [27:22] DATGAIN_VGA2GAIN_9_PREG — Receive data path equalization LUT VGA2 peaking control, entry 9
  [21:16] DATGAIN_VGA1GAIN_9_PREG — Receive data path equalization LUT VGA1 peaking control, entry 9
  [11:6] DATGAIN_VGA2GAIN_8_PREG — Receive data path equalization LUT VGA2 peaking control, entry 8
  [5:0] DATGAIN_VGA1GAIN_8_PREG — Receive data path equalization LUT VGA1 peaking control, entry 8
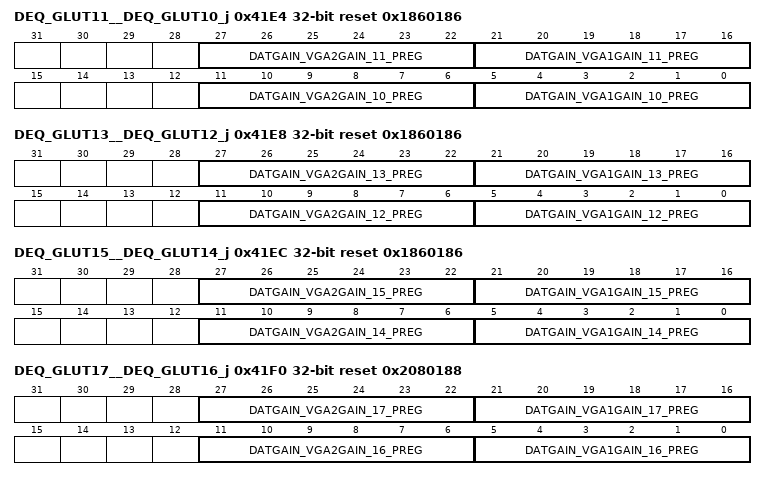
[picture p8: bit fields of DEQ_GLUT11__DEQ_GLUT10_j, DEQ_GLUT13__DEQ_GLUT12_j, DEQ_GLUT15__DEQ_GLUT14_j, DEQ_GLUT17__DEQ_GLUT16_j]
0x41E4 DEQ_GLUT11__DEQ_GLUT10_j reset 0x1860186 — Receive data path equalization LUT gain, entry 10 register. Offset = 41E4h + (j * 400h); where j = 0h to 1h
  [27:22] DATGAIN_VGA2GAIN_11_PREG — Receive data path equalization LUT VGA2 peaking control, entry 11
  [21:16] DATGAIN_VGA1GAIN_11_PREG — Receive data path equalization LUT VGA1 peaking control, entry 11
  [11:6] DATGAIN_VGA2GAIN_10_PREG — Receive data path equalization LUT VGA2 peaking control, entry 10
  [5:0] DATGAIN_VGA1GAIN_10_PREG — Receive data path equalization LUT VGA1 peaking control, entry 10
0x41E8 DEQ_GLUT13__DEQ_GLUT12_j reset 0x1860186 — Receive data path equalization LUT gain, entry 12 register. Offset = 41E8h + (j * 400h); where j = 0h to 1h
  [27:22] DATGAIN_VGA2GAIN_13_PREG — Receive data path equalization LUT VGA2 peaking control, entry 13
  [21:16] DATGAIN_VGA1GAIN_13_PREG — Receive data path equalization LUT VGA1 peaking control, entry 13
  [11:6] DATGAIN_VGA2GAIN_12_PREG — Receive data path equalization LUT VGA2 peaking control, entry 12
  [5:0] DATGAIN_VGA1GAIN_12_PREG — Receive data path equalization LUT VGA1 peaking control, entry 12
0x41EC DEQ_GLUT15__DEQ_GLUT14_j reset 0x1860186 — Receive data path equalization LUT gain, entry 14 register. Offset = 41ECh + (j * 400h); where j = 0h to 1h
  [27:22] DATGAIN_VGA2GAIN_15_PREG — Receive data path equalization LUT VGA2 peaking control, entry 15
  [21:16] DATGAIN_VGA1GAIN_15_PREG — Receive data path equalization LUT VGA1 peaking control, entry 15
  [11:6] DATGAIN_VGA2GAIN_14_PREG — Receive data path equalization LUT VGA2 peaking control, entry 14
  [5:0] DATGAIN_VGA1GAIN_14_PREG — Receive data path equalization LUT VGA1 peaking control, entry 14
0x41F0 DEQ_GLUT17__DEQ_GLUT16_j reset 0x2080188 — Receive data path equalization LUT gain, entry 16 register. Offset = 41F0h + (j * 400h); where j = 0h to 1h
  [27:22] DATGAIN_VGA2GAIN_17_PREG — Receive data path equalization LUT VGA2 peaking control, entry 17
  [21:16] DATGAIN_VGA1GAIN_17_PREG — Receive data path equalization LUT VGA1 peaking control, entry 17
  [11:6] DATGAIN_VGA2GAIN_16_PREG — Receive data path equalization LUT VGA2 peaking control, entry 16
  [5:0] DATGAIN_VGA1GAIN_16_PREG — Receive data path equalization LUT VGA1 peaking control, entry 16
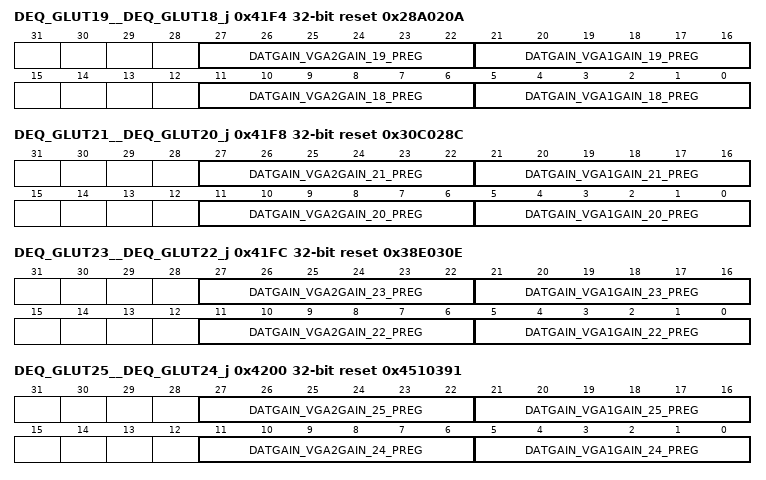
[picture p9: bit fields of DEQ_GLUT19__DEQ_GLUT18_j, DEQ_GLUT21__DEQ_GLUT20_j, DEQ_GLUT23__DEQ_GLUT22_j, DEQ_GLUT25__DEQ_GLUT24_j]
0x41F4 DEQ_GLUT19__DEQ_GLUT18_j reset 0x28A020A — Receive data path equalization LUT gain, entry 18 register. Offset = 41F4h + (j * 400h); where j = 0h to 1h
  [27:22] DATGAIN_VGA2GAIN_19_PREG — Receive data path equalization LUT VGA2 peaking control, entry 19
  [21:16] DATGAIN_VGA1GAIN_19_PREG — Receive data path equalization LUT VGA1 peaking control, entry 19
  [11:6] DATGAIN_VGA2GAIN_18_PREG — Receive data path equalization LUT VGA2 peaking control, entry 18
  [5:0] DATGAIN_VGA1GAIN_18_PREG — Receive data path equalization LUT VGA1 peaking control, entry 18
0x41F8 DEQ_GLUT21__DEQ_GLUT20_j reset 0x30C028C — Receive data path equalization LUT gain, entry 20 register. Offset = 41F8h + (j * 400h); where j = 0h to 1h
  [27:22] DATGAIN_VGA2GAIN_21_PREG — Receive data path equalization LUT VGA2 peaking control, entry 21
  [21:16] DATGAIN_VGA1GAIN_21_PREG — Receive data path equalization LUT VGA1 peaking control, entry 21
  [11:6] DATGAIN_VGA2GAIN_20_PREG — Receive data path equalization LUT VGA2 peaking control, entry 20
  [5:0] DATGAIN_VGA1GAIN_20_PREG — Receive data path equalization LUT VGA1 peaking control, entry 20
0x41FC DEQ_GLUT23__DEQ_GLUT22_j reset 0x38E030E — Receive data path equalization LUT gain, entry 22 register. Offset = 41FCh + (j * 400h); where j = 0h to 1h
  [27:22] DATGAIN_VGA2GAIN_23_PREG — Receive data path equalization LUT VGA2 peaking control, entry 23
  [21:16] DATGAIN_VGA1GAIN_23_PREG — Receive data path equalization LUT VGA1 peaking control, entry 23
  [11:6] DATGAIN_VGA2GAIN_22_PREG — Receive data path equalization LUT VGA2 peaking control, entry 22
  [5:0] DATGAIN_VGA1GAIN_22_PREG — Receive data path equalization LUT VGA1 peaking control, entry 22
0x4200 DEQ_GLUT25__DEQ_GLUT24_j reset 0x4510391 — Receive data path equalization LUT gain, entry 24 register. Offset = 4200h + (j * 400h); where j = 0h to 1h
  [27:22] DATGAIN_VGA2GAIN_25_PREG — Receive data path equalization LUT VGA2 peaking control, entry 25
  [21:16] DATGAIN_VGA1GAIN_25_PREG — Receive data path equalization LUT VGA1 peaking control, entry 25
  [11:6] DATGAIN_VGA2GAIN_24_PREG — Receive data path equalization LUT VGA2 peaking control, entry 24
  [5:0] DATGAIN_VGA1GAIN_24_PREG — Receive data path equalization LUT VGA1 peaking control, entry 24
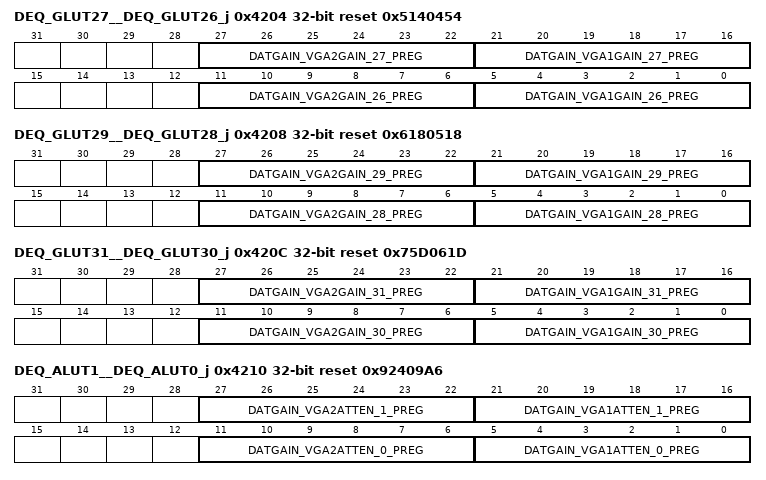
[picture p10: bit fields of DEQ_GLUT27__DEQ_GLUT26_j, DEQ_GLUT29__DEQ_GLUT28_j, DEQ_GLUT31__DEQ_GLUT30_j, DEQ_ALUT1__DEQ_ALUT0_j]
0x4204 DEQ_GLUT27__DEQ_GLUT26_j reset 0x5140454 — Receive data path equalization LUT gain, entry 26 register. Offset = 4204h + (j * 400h); where j = 0h to 1h
  [27:22] DATGAIN_VGA2GAIN_27_PREG — Receive data path equalization LUT VGA2 peaking control, entry 27
  [21:16] DATGAIN_VGA1GAIN_27_PREG — Receive data path equalization LUT VGA1 peaking control, entry 27
  [11:6] DATGAIN_VGA2GAIN_26_PREG — Receive data path equalization LUT VGA2 peaking control, entry 26
  [5:0] DATGAIN_VGA1GAIN_26_PREG — Receive data path equalization LUT VGA1 peaking control, entry 26
0x4208 DEQ_GLUT29__DEQ_GLUT28_j reset 0x6180518 — Receive data path equalization LUT gain, entry 28 register. Offset = 4208h + (j * 400h); where j = 0h to 1h
  [27:22] DATGAIN_VGA2GAIN_29_PREG — Receive data path equalization LUT VGA2 peaking control, entry 29
  [21:16] DATGAIN_VGA1GAIN_29_PREG — Receive data path equalization LUT VGA1 peaking control, entry 29
  [11:6] DATGAIN_VGA2GAIN_28_PREG — Receive data path equalization LUT VGA2 peaking control, entry 28
  [5:0] DATGAIN_VGA1GAIN_28_PREG — Receive data path equalization LUT VGA1 peaking control, entry 28
0x420C DEQ_GLUT31__DEQ_GLUT30_j reset 0x75D061D — Receive data path equalization LUT gain, entry 30 register. Offset = 420Ch + (j * 400h); where j = 0h to 1h
  [27:22] DATGAIN_VGA2GAIN_31_PREG — Receive data path equalization LUT VGA2 peaking control, entry 31
  [21:16] DATGAIN_VGA1GAIN_31_PREG — Receive data path equalization LUT VGA1 peaking control, entry 31
  [11:6] DATGAIN_VGA2GAIN_30_PREG — Receive data path equalization LUT VGA2 peaking control, entry 30
  [5:0] DATGAIN_VGA1GAIN_30_PREG — Receive data path equalization LUT VGA1 peaking control, entry 30
0x4210 DEQ_ALUT1__DEQ_ALUT0_j reset 0x92409A6 — Receive data path equalization LUT attenuation, entry 0 register. Offset = 4210h + (j * 400h); where j = 0h to 1h
  [27:22] DATGAIN_VGA2ATTEN_1_PREG — Receive data path equalization LUT VGA2 attenuation control, entry 1
  [21:16] DATGAIN_VGA1ATTEN_1_PREG — Receive data path equalization LUT VGA1 attenuation control, entry 1
  [11:6] DATGAIN_VGA2ATTEN_0_PREG — Receive data path equalization LUT VGA2 attenuation control, entry 0
  [5:0] DATGAIN_VGA1ATTEN_0_PREG — Receive data path equalization LUT VGA1 attenuation control, entry 0
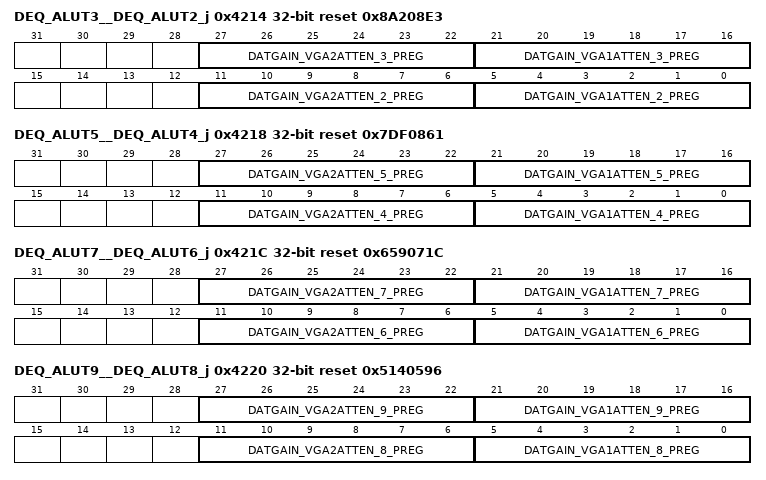
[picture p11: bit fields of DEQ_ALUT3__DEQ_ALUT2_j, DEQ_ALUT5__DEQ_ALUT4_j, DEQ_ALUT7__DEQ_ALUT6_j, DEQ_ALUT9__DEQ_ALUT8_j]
0x4214 DEQ_ALUT3__DEQ_ALUT2_j reset 0x8A208E3 — Receive data path equalization LUT attenuation, entry 2 register. Offset = 4214h + (j * 400h); where j = 0h to 1h
  [27:22] DATGAIN_VGA2ATTEN_3_PREG — Receive data path equalization LUT VGA2 attenuation control, entry 3
  [21:16] DATGAIN_VGA1ATTEN_3_PREG — Receive data path equalization LUT VGA1 attenuation control, entry 3
  [11:6] DATGAIN_VGA2ATTEN_2_PREG — Receive data path equalization LUT VGA2 attenuation control, entry 2
  [5:0] DATGAIN_VGA1ATTEN_2_PREG — Receive data path equalization LUT VGA1 attenuation control, entry 2
0x4218 DEQ_ALUT5__DEQ_ALUT4_j reset 0x7DF0861 — Receive data path equalization LUT attenuation, entry 4 register. Offset = 4218h + (j * 400h); where j = 0h to 1h
  [27:22] DATGAIN_VGA2ATTEN_5_PREG — Receive data path equalization LUT VGA2 attenuation control, entry 5
  [21:16] DATGAIN_VGA1ATTEN_5_PREG — Receive data path equalization LUT VGA1 attenuation control, entry 5
  [11:6] DATGAIN_VGA2ATTEN_4_PREG — Receive data path equalization LUT VGA2 attenuation control, entry 4
  [5:0] DATGAIN_VGA1ATTEN_4_PREG — Receive data path equalization LUT VGA1 attenuation control, entry 4
0x421C DEQ_ALUT7__DEQ_ALUT6_j reset 0x659071C — Receive data path equalization LUT attenuation, entry 6 register. Offset = 421Ch + (j * 400h); where j = 0h to 1h
  [27:22] DATGAIN_VGA2ATTEN_7_PREG — Receive data path equalization LUT VGA2 attenuation control, entry 7
  [21:16] DATGAIN_VGA1ATTEN_7_PREG — Receive data path equalization LUT VGA1 attenuation control, entry 7
  [11:6] DATGAIN_VGA2ATTEN_6_PREG — Receive data path equalization LUT VGA2 attenuation control, entry 6
  [5:0] DATGAIN_VGA1ATTEN_6_PREG — Receive data path equalization LUT VGA1 attenuation control, entry 6
0x4220 DEQ_ALUT9__DEQ_ALUT8_j reset 0x5140596 — Receive data path equalization LUT attenuation, entry 8 register. Offset = 4220h + (j * 400h); where j = 0h to 1h
  [27:22] DATGAIN_VGA2ATTEN_9_PREG — Receive data path equalization LUT VGA2 attenuation control, entry 9
  [21:16] DATGAIN_VGA1ATTEN_9_PREG — Receive data path equalization LUT VGA1 attenuation control, entry 9
  [11:6] DATGAIN_VGA2ATTEN_8_PREG — Receive data path equalization LUT VGA2 attenuation control, entry 8
  [5:0] DATGAIN_VGA1ATTEN_8_PREG — Receive data path equalization LUT VGA1 attenuation control, entry 8
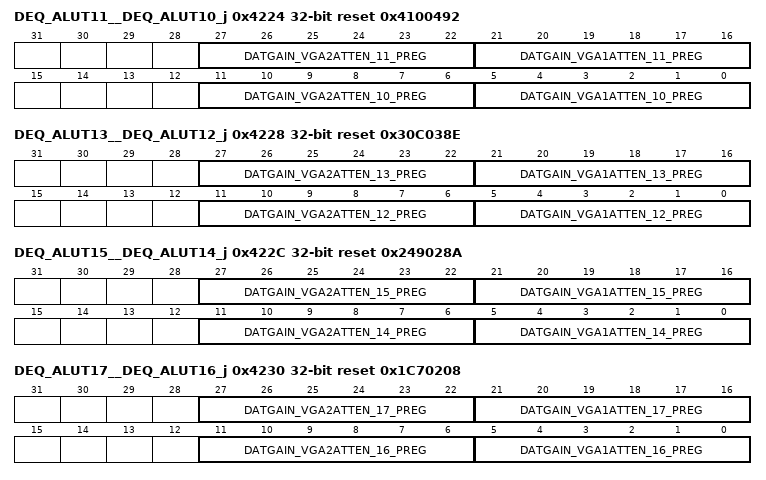
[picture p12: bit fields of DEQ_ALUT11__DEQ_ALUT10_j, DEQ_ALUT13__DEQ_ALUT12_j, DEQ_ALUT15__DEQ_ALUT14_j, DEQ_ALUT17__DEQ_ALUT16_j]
0x4224 DEQ_ALUT11__DEQ_ALUT10_j reset 0x4100492 — Receive data path equalization LUT attenuation, entry 10 register. Offset = 4224h + (j * 400h); where j = 0h to 1h
  [27:22] DATGAIN_VGA2ATTEN_11_PREG — Receive data path equalization LUT VGA2 attenuation control, entry 11
  [21:16] DATGAIN_VGA1ATTEN_11_PREG — Receive data path equalization LUT VGA1 attenuation control, entry 11
  [11:6] DATGAIN_VGA2ATTEN_10_PREG — Receive data path equalization LUT VGA2 attenuation control, entry 10
  [5:0] DATGAIN_VGA1ATTEN_10_PREG — Receive data path equalization LUT VGA1 attenuation control, entry 10
0x4228 DEQ_ALUT13__DEQ_ALUT12_j reset 0x30C038E — Receive data path equalization LUT attenuation, entry 12 register. Offset = 4228h + (j * 400h); where j = 0h to 1h
  [27:22] DATGAIN_VGA2ATTEN_13_PREG — Receive data path equalization LUT VGA2 attenuation control, entry 13
  [21:16] DATGAIN_VGA1ATTEN_13_PREG — Receive data path equalization LUT VGA1 attenuation control, entry 13
  [11:6] DATGAIN_VGA2ATTEN_12_PREG — Receive data path equalization LUT VGA2 attenuation control, entry 12
  [5:0] DATGAIN_VGA1ATTEN_12_PREG — Receive data path equalization LUT VGA1 attenuation control, entry 12
0x422C DEQ_ALUT15__DEQ_ALUT14_j reset 0x249028A — Receive data path equalization LUT attenuation, entry 14 register. Offset = 422Ch + (j * 400h); where j = 0h to 1h
  [27:22] DATGAIN_VGA2ATTEN_15_PREG — Receive data path equalization LUT VGA2 attenuation control, entry 15
  [21:16] DATGAIN_VGA1ATTEN_15_PREG — Receive data path equalization LUT VGA1 attenuation control, entry 15
  [11:6] DATGAIN_VGA2ATTEN_14_PREG — Receive data path equalization LUT VGA2 attenuation control, entry 14
  [5:0] DATGAIN_VGA1ATTEN_14_PREG — Receive data path equalization LUT VGA1 attenuation control, entry 14
0x4230 DEQ_ALUT17__DEQ_ALUT16_j reset 0x1C70208 — Receive data path equalization LUT attenuation, entry 16 register. Offset = 4230h + (j * 400h); where j = 0h to 1h
  [27:22] DATGAIN_VGA2ATTEN_17_PREG — Receive data path equalization LUT VGA2 attenuation control, entry 17
  [21:16] DATGAIN_VGA1ATTEN_17_PREG — Receive data path equalization LUT VGA1 attenuation control, entry 17
  [11:6] DATGAIN_VGA2ATTEN_16_PREG — Receive data path equalization LUT VGA2 attenuation control, entry 16
  [5:0] DATGAIN_VGA1ATTEN_16_PREG — Receive data path equalization LUT VGA1 attenuation control, entry 16
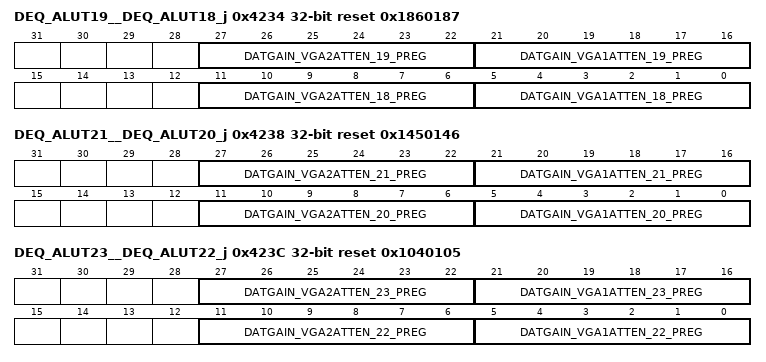
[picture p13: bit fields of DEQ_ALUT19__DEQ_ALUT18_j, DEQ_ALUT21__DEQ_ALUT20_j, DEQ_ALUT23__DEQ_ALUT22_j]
0x4234 DEQ_ALUT19__DEQ_ALUT18_j reset 0x1860187 — Receive data path equalization LUT attenuation, entry 18 register. Offset = 4234h + (j * 400h); where j = 0h to 1h
  [27:22] DATGAIN_VGA2ATTEN_19_PREG — Receive data path equalization LUT VGA2 attenuation control, entry 19
  [21:16] DATGAIN_VGA1ATTEN_19_PREG — Receive data path equalization LUT VGA1 attenuation control, entry 19
  [11:6] DATGAIN_VGA2ATTEN_18_PREG — Receive data path equalization LUT VGA2 attenuation control, entry 18
  [5:0] DATGAIN_VGA1ATTEN_18_PREG — Receive data path equalization LUT VGA1 attenuation control, entry 18
0x4238 DEQ_ALUT21__DEQ_ALUT20_j reset 0x1450146 — Receive data path equalization LUT attenuation, entry 20 register. Offset = 4238h + (j * 400h); where j = 0h to 1h
  [27:22] DATGAIN_VGA2ATTEN_21_PREG — Receive data path equalization LUT VGA2 attenuation control, entry 21
  [21:16] DATGAIN_VGA1ATTEN_21_PREG — Receive data path equalization LUT VGA1 attenuation control, entry 21
  [11:6] DATGAIN_VGA2ATTEN_20_PREG — Receive data path equalization LUT VGA2 attenuation control, entry 20
  [5:0] DATGAIN_VGA1ATTEN_20_PREG — Receive data path equalization LUT VGA1 attenuation control, entry 20
0x423C DEQ_ALUT23__DEQ_ALUT22_j reset 0x1040105 — Receive data path equalization LUT attenuation, entry 22 register. Offset = 423Ch + (j * 400h); where j = 0h to 1h
  [27:22] DATGAIN_VGA2ATTEN_23_PREG — Receive data path equalization LUT VGA2 attenuation control, entry 23
  [21:16] DATGAIN_VGA1ATTEN_23_PREG — Receive data path equalization LUT VGA1 attenuation control, entry 23
  [11:6] DATGAIN_VGA2ATTEN_22_PREG — Receive data path equalization LUT VGA2 attenuation control, entry 22
  [5:0] DATGAIN_VGA1ATTEN_22_PREG — Receive data path equalization LUT VGA1 attenuation control, entry 22
